# R7FA6T1 register map
Vendor: Renesas; Series: RA6; File version: 1.2
CPU: CM4 r0p1, little endian, MPU, FPU, VTOR, 4 interrupt priority bits
Registers are 8-bit, read-write, reset 0x0 unless marked. A register's access mark holds for its fields unless they carry their own. Offsets are from the block's base; [hi:lo] are bit positions; 'fields as' and 'values as' point back to an identical list.

## WDT — Watchdog Timer
Base 0x40044200
0x00 WDTRR reset 0xFF — WDT Refresh Register
  [7:0] WDTRR — WDTRR is an 8-bit register that refreshes the down-counter of the WDT.
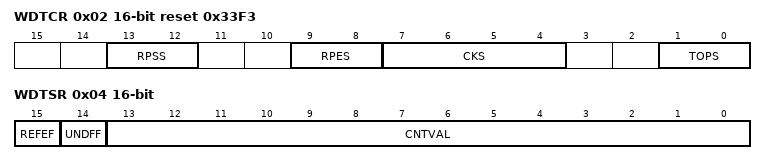
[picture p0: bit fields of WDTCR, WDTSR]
0x02 WDTCR 16-bit reset 0x33F3 — WDT Control Register
  [13:12] RPSS — Window Start Position Selection
    0=25 percent; 1=50 percent; 2=75 percent; 3=100 percent (window start position is not specified)
  [9:8] RPES — Window End Position Selection
    0=75 percent; 1=50 percent; 2=25 percent; 3=0 percent (window end position is not specified)
  [7:4] CKS — Clock Division Ratio Selection
    1=PCLK/4; 4=PCLK/64; 15=PCLK/128; 6=PCLK/512; 7=PCLK/2048; 8=PCLK/8192; other=others (setting prohibited)
  [1:0] TOPS — Timeout Period Selection
    0=1,024 cycles (03FFh); 1=4,096 cycles (0FFFh); 2=8,192 cycles (1FFFh); 3=16,384 cycles (3FFFh)
0x04 WDTSR 16-bit — WDT Status Register
  [15] REFEF write-0-clears read-modifies — Refresh Error Flag
    0=No refresh error occurred; 1=Refresh error occurred
  [14] UNDFF write-0-clears read-modifies — Underflow Flag
    0=No underflow occurred; 1=Underflow occurred
  [13:0] CNTVAL ro — Down-Counter ValueValue counted by the down-counter
0x06 WDTRCR reset 0x80 — WDT Reset Control Register
  [7] RSTIRQS — Reset Interrupt Request Selection
    0=Non-maskable interrupt request or interrupt request output is enabled; 1=Reset output is enabled
0x08 WDTCSTPR reset 0x80 — WDT Count Stop Control Register
  [7] SLCSTP — Sleep-Mode Count Stop Control
    0=Count stop is disabled; 1=Count is stopped at a transition to sleep mode

## IWDT — Independent Watchdog Timer
Base 0x40044400
0x00 IWDTRR reset 0xFF — IWDT Refresh Register
  [7:0] IWDTRR — The counter is refreshed by writing 0x00 and then writing 0xFF to this register.
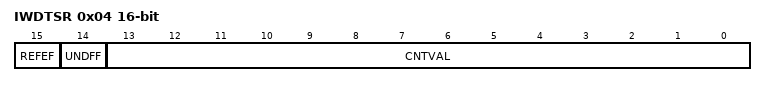
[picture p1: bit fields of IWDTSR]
0x04 IWDTSR 16-bit — IWDT Status Register
  [15] REFEF write-0-clears read-modifies — Refresh Error Flag
    0=Refresh error not occurred; 1=Refresh error occurred
  [14] UNDFF write-0-clears read-modifies — Underflow Flag
    0=Underflow not occurred; 1=Underflow occurred
  [13:0] CNTVAL ro — Counter ValueValue counted by the counter

## CAC — Clock Frequency Accuracy Measurement Circuit
Base 0x40044600
0x00 CACR0 — CAC Control Register 0
  [0] CFME — Clock Frequency Measurement Enable.
    0=Disable; 1=Enable
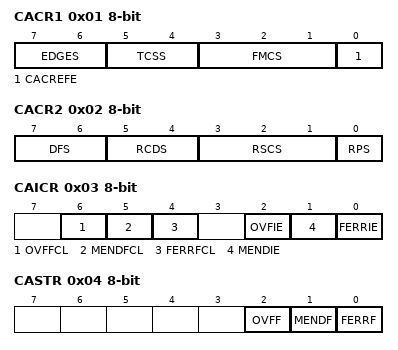
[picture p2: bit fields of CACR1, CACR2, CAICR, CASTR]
0x01 CACR1 — CAC Control Register 1
  [7:6] EDGES — Valid Edge Select
    0=Rising edge; 1=Falling edge; 2=Both rising and falling edges; 3=Setting prohibited
  [5:4] TCSS — Measurement Target Clock Frequency Division Ratio Select
    0=No division; 1=x 1/4 clock; 2=x 1/8 clock; 3=x 1/32 clock
  [3:1] FMCS — Measurement Target Clock Select
    0=Main clock; 1=Sub-clock; 2=HOCO clock; 3=MOCO clock; 4=LOCO clock; 5=Peripheral module clock(PCLKB); 6=IWDTCLK clock; 7=Setting prohibited
  [0] CACREFE — CACREF Pin Input Enable
    0=Disable; 1=Enable
0x02 CACR2 — CAC Control Register 2
  [7:6] DFS — Digital Filter Selection
    0=Digital filtering is disabled; 1=The sampling clock for the digital filter is the frequency measuring clock; 2=The sampling clock for the digital filter is the frequency measuring clock divided by 4; 3=The sampling clock for the digital filter is the frequency measuring clock divided by 16
  [5:4] RCDS — Measurement Reference Clock Frequency Division Ratio Select
    0=1/32 clock; 1=1/128 clock; 2=1/1024 clock; 3=1/8192 clock
  [3:1] RSCS — Measurement Reference Clock Select
    values as CACR1.FMCS
  [0] RPS — Reference Signal Select
    0=CACREF pin input; 1=Internal clock (internally generated signal)
0x03 CAICR — CAC Interrupt Control Register
  [6] OVFFCL wo — OVFF Clear
    0=No effect on operations; 1=Clears the OVFF flag
  [5] MENDFCL wo — MENDF Clear
    0=No effect on operations; 1=Clears the MENDF flag
  [4] FERRFCL wo — FERRF Clear
    0=No effect on operations; 1=Clears the FERRF flag
  [2] OVFIE — Overflow Interrupt Request Enable
    0=Disable; 1=Enable
  [1] MENDIE — Measurement End Interrupt Request Enable
    0=Disable; 1=Enable
  [0] FERRIE — Frequency Error Interrupt Request Enable
    0=Disable; 1=Enable
0x04 CASTR ro — CAC Status Register
  [2] OVFF — Counter Overflow Flag
    0=The counter has not overflowed; 1=The counter has overflowed
  [1] MENDF — Measurement End Flag
    0=Measurement is in progress; 1=Measurement has ended
  [0] FERRF — Frequency Error Flag
    0=The clock frequency is within the range corresponding to the settings; 1=The clock frequency has deviated beyond the range corresponding to the settings (frequency error)
0x06 CAULVR 16-bit — CAC Upper-Limit Value Setting Register
  [15:0] CAULVR — CAULVR is a 16-bit readable/writable register that stores the upper-limit value of the frequency.
0x08 CALLVR 16-bit — CAC Lower-Limit Value Setting Register
  [15:0] CALLVR — CALLVR is a 16-bit readable/writable register that stores the lower-limit value of the frequency.
0x0A CACNTBR 16-bit ro — CAC Counter Buffer Register
  [15:0] CACNTBR — CACNTBR is a 16-bit read-only register that retains the counter value at the time a valid reference signal edge is input
